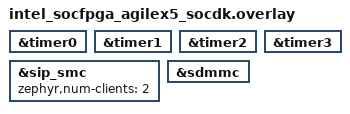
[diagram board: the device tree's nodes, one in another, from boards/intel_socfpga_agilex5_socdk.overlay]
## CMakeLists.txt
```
# SPDX-License-Identifier: Apache-2.0

cmake_minimum_required(VERSION 3.20.0)
find_package(Zephyr REQUIRED HINTS $ENV{ZEPHYR_BASE})
project(shell_module)

target_sources(app PRIVATE src/main.c src/test_module.c)
target_sources_ifdef(CONFIG_SHELL_DYNAMIC_CMDS app PRIVATE src/dynamic_cmd.c)
target_sources_ifdef(CONFIG_SHELL_BACKEND_SERIAL app PRIVATE src/uart_reinit.c)
```

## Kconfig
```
# Config options for logger sample app

# Copyright (c) 2018 Nordic Semiconductor ASA
# SPDX-License-Identifier: Apache-2.0

mainmenu "Shell module sample application"

menu "Application configuration"

config SHELL_FOREGROUND_CMDS
	bool "Shell foreground commands example"
	default y

config SHELL_DYNAMIC_CMDS
	bool "Shell dynamic commands example"
	default y

endmenu

source "Kconfig.zephyr"
```

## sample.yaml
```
sample:
  name: Shell Sample
common:
  filter: not CONFIG_NATIVE_LIBC
  platform_exclude:
    - native_posix
    - native_posix/native/64
tests:
  sample.shell.shell_module:
    filter: CONFIG_SERIAL and dt_chosen_enabled("zephyr,shell-uart")
    tags: shell
    harness: keyboard
    min_ram: 40
    integration_platforms:
      - native_sim
      - intel_socfpga_agilex5_socdk
  sample.shell.shell_module.usb:
    depends_on: usb_device
    tags:
      - shell
      - usb
    harness: keyboard
    min_ram: 40
    extra_args:
      - OVERLAY_CONFIG="overlay-usb.conf"
      - DTC_OVERLAY_FILE="usb.overlay"
    integration_platforms:
      - native_sim
  sample.shell.shell_module.minimal:
    filter: CONFIG_SERIAL and dt_chosen_enabled("zephyr,shell-uart")
    tags: shell
    harness: keyboard
    extra_args: CONF_FILE="prj_minimal.conf"
    integration_platforms:
      - native_sim
  sample.shell.shell_module.getopt:
    integration_platforms:
      - qemu_x86
    arch_exclude: posix
    filter: CONFIG_SERIAL and dt_chosen_enabled("zephyr,shell-uart") and not CONFIG_NEWLIB_LIBC
    tags: shell
    harness: keyboard
    min_ram: 40
    extra_args: CONF_FILE="prj_getopt.conf"
  sample.shell.shell_module.minimal_rtt:
    filter: CONFIG_HAS_SEGGER_RTT
    tags: shell
    harness: keyboard
    extra_args: CONF_FILE="prj_minimal_rtt.conf"
    integration_platforms:
      - nrf52833dk/nrf52833
  sample.shell.shell_module.bt:
    platform_allow:
      - nrf52840dk/nrf52840
    integration_platforms:
      - nrf52840dk/nrf52840
    tags:
      - shell
      - bluetooth
    filter: CONFIG_DT_HAS_ZEPHYR_NUS_UART_ENABLED
    harness: bluetooth_nus
    arch_exclude:
      - posix
    extra_args:
      - OVERLAY_CONFIG="overlay-bt.conf"
      - DTC_OVERLAY_FILE="bt.overlay"
  sample.shell.shell_module.login:
    filter: CONFIG_SERIAL and dt_chosen_enabled("zephyr,shell-uart")
    tags: shell
    harness: keyboard
    min_ram: 40
    extra_args: CONF_FILE="prj_login.conf"
    integration_platforms:
      - native_sim
  sample.shell.shell_module.robot:
    harness: robot
    harness_config:
      robot_testsuite: shell_module.robot
```

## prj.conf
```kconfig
CONFIG_PRINTK=y
CONFIG_SHELL=y
CONFIG_LOG=y
CONFIG_LOG_CMDS=y
CONFIG_INIT_STACKS=y
CONFIG_THREAD_STACK_INFO=y
CONFIG_KERNEL_SHELL=y
CONFIG_THREAD_MONITOR=y
CONFIG_BOOT_BANNER=n
CONFIG_THREAD_NAME=y
CONFIG_DEVICE_SHELL=y
CONFIG_POSIX_API=y
CONFIG_POSIX_TIMERS=y
CONFIG_DATE_SHELL=y
CONFIG_THREAD_RUNTIME_STATS=y
CONFIG_THREAD_RUNTIME_STATS_USE_TIMING_FUNCTIONS=y
CONFIG_STATS=y
CONFIG_STATS_SHELL=y
```

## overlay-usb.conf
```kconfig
CONFIG_USB_DEVICE_STACK=y
CONFIG_USB_DEVICE_PRODUCT="Zephyr USB shell sample"
CONFIG_SHELL_BACKEND_SERIAL_CHECK_DTR=y
CONFIG_UART_LINE_CTRL=y
CONFIG_USB_DEVICE_INITIALIZE_AT_BOOT=n

# POSIX_TIMERS requires an embedded C library while the native USB driver is incompatible with it.
# So let's disable it. Once USB_NATIVE_POSIX supports embedded C libraries this can be removed.
CONFIG_POSIX_API=n
CONFIG_POSIX_TIMERS=n
# DATE_SHELL requires POSIX_TIMERS
CONFIG_DATE_SHELL=n
```

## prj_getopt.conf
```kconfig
CONFIG_PRINTK=y
CONFIG_SHELL=y
CONFIG_SHELL_GETOPT=y
CONFIG_LOG=y
CONFIG_INIT_STACKS=y
CONFIG_THREAD_STACK_INFO=y
CONFIG_KERNEL_SHELL=y
CONFIG_THREAD_MONITOR=y
CONFIG_BOOT_BANNER=n
CONFIG_THREAD_NAME=y
CONFIG_DEVICE_SHELL=y
CONFIG_POSIX_API=y
CONFIG_POSIX_TIMERS=y
CONFIG_DATE_SHELL=y
CONFIG_THREAD_RUNTIME_STATS=y
```

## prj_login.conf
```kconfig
CONFIG_PRINTK=y
CONFIG_SHELL=y
CONFIG_LOG=y
CONFIG_INIT_STACKS=y
CONFIG_THREAD_STACK_INFO=y
CONFIG_KERNEL_SHELL=y
CONFIG_THREAD_MONITOR=y
CONFIG_BOOT_BANNER=n
CONFIG_THREAD_NAME=y
CONFIG_DEVICE_SHELL=y
CONFIG_POSIX_API=y
CONFIG_POSIX_TIMERS=y
CONFIG_DATE_SHELL=y
CONFIG_THREAD_RUNTIME_STATS=y

CONFIG_SHELL_CMDS_SELECT=y
CONFIG_SHELL_START_OBSCURED=y
CONFIG_SHELL_PROMPT_UART="login: "
CONFIG_SHELL_CMD_ROOT="login"
```

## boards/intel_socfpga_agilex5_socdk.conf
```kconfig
# Copyright (c) 2022-2023, Intel Corporation.
# SPDX-License-Identifier: Apache-2.0

# Misc
CONFIG_HEAP_MEM_POOL_SIZE=16384
CONFIG_SHELL_STACK_SIZE=8192

# Setting the max argc
CONFIG_SHELL_ARGC_MAX=12

# Enable the Zephyr boot banner
CONFIG_BOOT_BANNER=y

# Enable timer driver
CONFIG_COUNTER=y

# Enable Timer shell commands
CONFIG_COUNTER_SHELL=y

#SiP SVC Service
CONFIG_ARM_SIP_SVC_DRIVER=y
CONFIG_ARM_SIP_SVC_SUBSYS=y
CONFIG_ARM_SIP_SVC_SUBSYS_SINGLY_OPEN=y

#SiP SVC Service Shell
CONFIG_ARM_SIP_SVC_SUBSYS_SHELL=y

# Enable File System Shell
CONFIG_FILE_SYSTEM_SHELL=y

# Enable Disk access
CONFIG_DISK_ACCESS=y

# File System Setting
CONFIG_FILE_SYSTEM=y
CONFIG_FAT_FILESYSTEM_ELM=y

# Enable SDMMC
CONFIG_DISK_DRIVER_SDMMC=y

# Enable SDHC
CONFIG_SDHC=y
```

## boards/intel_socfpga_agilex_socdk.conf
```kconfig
# Copyright (c) 2023, Intel Corporation.
# SPDX-License-Identifier: Apache-2.0

# Misc
CONFIG_HEAP_MEM_POOL_SIZE=16384
CONFIG_SHELL_STACK_SIZE=8192

# Setting the max argc
CONFIG_SHELL_ARGC_MAX=12

# Enable the Zephyr boot banner
CONFIG_BOOT_BANNER=y

#SiP SVC Service
CONFIG_ARM_SIP_SVC_DRIVER=y
CONFIG_ARM_SIP_SVC_SUBSYS=y
CONFIG_ARM_SIP_SVC_SUBSYS_SINGLY_OPEN=y

#SiP SVC Service Shell
CONFIG_ARM_SIP_SVC_SUBSYS_SHELL=y
```

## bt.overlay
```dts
/*
 * Copyright (c) 2024 Croxel, Inc.
 *
 * SPDX-License-Identifier: Apache-2.0
 */

/ {
	chosen {
		zephyr,console = &bt_nus_console_uart;
		zephyr,shell-uart = &bt_nus_console_uart;
	};

	bt_nus_console_uart: bt_nus_console_uart {
		compatible = "zephyr,nus-uart";
		rx-fifo-size = <1024>;
		tx-fifo-size = <1024>;
	};
};
```

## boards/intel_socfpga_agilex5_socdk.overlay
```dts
/*
 * Copyright (C) 2023 Intel Corporation
 * SPDX-License-Identifier: Apache-2.0
 */

/*
 * The overlay file should be used to enable any
 * dts nodes required by this shell application for this
 * board.
 *
 * Nothing here as of now.
 */

&timer0 {
	status = "okay";
};

&timer1 {
	status = "okay";
};

&timer2 {
	status = "okay";
};

&timer3 {
	status = "okay";
};

&sip_smc {
	status = "okay";
	zephyr,num-clients = <2>;
};

&sdmmc {
	status = "okay";
};
```

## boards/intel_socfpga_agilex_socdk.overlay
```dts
/*
 * Copyright (C) 2023 Intel Corporation
 * SPDX-License-Identifier: Apache-2.0
 */

/*
 * The overlay file should be used to enable any
 * dts nodes required by this shell application for this
 * board.
 */

&sip_smc {
	status = "okay";
	zephyr,num-clients = <2>;
};
```

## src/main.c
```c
/*
 * Copyright (c) 2015 Intel Corporation
 *
 * SPDX-License-Identifier: Apache-2.0
 */

#include <zephyr/kernel.h>
#include <zephyr/shell/shell.h>
#include <zephyr/version.h>
#include <zephyr/logging/log.h>
#include <stdlib.h>
#include <zephyr/drivers/uart.h>
#include <zephyr/usb/usb_device.h>
#include <ctype.h>

#ifdef CONFIG_ARCH_POSIX
#include <unistd.h>
#else
#include <zephyr/posix/unistd.h>
#endif

LOG_MODULE_REGISTER(app);

extern void foo(void);

void timer_expired_handler(struct k_timer *timer)
{
	LOG_INF("Timer expired.");

	/* Call another module to present logging from multiple sources. */
	foo();
}

K_TIMER_DEFINE(log_timer, timer_expired_handler, NULL);

static int cmd_log_test_start(const struct shell *sh, size_t argc,
			      char **argv, uint32_t period)
{
	ARG_UNUSED(argv);

	k_timer_start(&log_timer, K_MSEC(period), K_MSEC(period));
	shell_print(sh, "Log test started\n");

	return 0;
}

static int cmd_log_test_start_demo(const struct shell *sh, size_t argc,
				   char **argv)
{
	return cmd_log_test_start(sh, argc, argv, 200);
}

static int cmd_log_test_start_flood(const struct shell *sh, size_t argc,
				    char **argv)
{
	return cmd_log_test_start(sh, argc, argv, 10);
}

static int cmd_log_test_stop(const struct shell *sh, size_t argc,
			     char **argv)
{
	ARG_UNUSED(argc);
	ARG_UNUSED(argv);

	k_timer_stop(&log_timer);
	shell_print(sh, "Log test stopped");

	return 0;
}

SHELL_STATIC_SUBCMD_SET_CREATE(sub_log_test_start,
	SHELL_CMD_ARG(demo, NULL,
		  "Start log timer which generates log message every 200ms.",
		  cmd_log_test_start_demo, 1, 0),
	SHELL_CMD_ARG(flood, NULL,
		  "Start log timer which generates log message every 10ms.",
		  cmd_log_test_start_flood, 1, 0),
	SHELL_SUBCMD_SET_END /* Array terminated. */
);
SHELL_STATIC_SUBCMD_SET_CREATE(sub_log_test,
	SHELL_CMD_ARG(start, &sub_log_test_start, "Start log test", NULL, 2, 0),
	SHELL_CMD_ARG(stop, NULL, "Stop log test.", cmd_log_test_stop, 1, 0),
	SHELL_SUBCMD_SET_END /* Array terminated. */
);

SHELL_CMD_REGISTER(log_test, &sub_log_test, "Log test", NULL);

static int cmd_demo_ping(const struct shell *sh, size_t argc, char **argv)
{
	ARG_UNUSED(argc);
	ARG_UNUSED(argv);

	shell_print(sh, "pong");

	return 0;
}

static int cmd_demo_board(const struct shell *sh, size_t argc, char **argv)
{
	ARG_UNUSED(argc);
	ARG_UNUSED(argv);

	shell_print(sh, CONFIG_BOARD);

	return 0;
}

#if defined CONFIG_SHELL_GETOPT
/* Thread save usage */
static int cmd_demo_getopt_ts(const struct shell *sh, size_t argc,
			      char **argv)
{
	struct getopt_state *state;
	char *cvalue = NULL;
	int aflag = 0;
	int bflag = 0;
	int c;

	while ((c = getopt(argc, argv, "abhc:")) != -1) {
		state = getopt_state_get();
		switch (c) {
		case 'a':
			aflag = 1;
			break;
		case 'b':
			bflag = 1;
			break;
		case 'c':
			cvalue = state->optarg;
			break;
		case 'h':
			/* When getopt is active shell is not parsing
			 * command handler to print help message. It must
			 * be done explicitly.
			 */
			shell_help(sh);
			return SHELL_CMD_HELP_PRINTED;
		case '?':
			if (state->optopt == 'c') {
				shell_print(sh,
					"Option -%c requires an argument.",
					state->optopt);
			} else if (isprint(state->optopt) != 0) {
				shell_print(sh,
					"Unknown option `-%c'.",
					state->optopt);
			} else {
				shell_print(sh,
					"Unknown option character `\\x%x'.",
					state->optopt);
			}
			return 1;
		default:
			break;
		}
	}

	shell_print(sh, "aflag = %d, bflag = %d", aflag, bflag);
	return 0;
}

static int cmd_demo_getopt(const struct shell *sh, size_t argc,
			      char **argv)
{
	char *cvalue = NULL;
	int aflag = 0;
	int bflag = 0;
	int c;

	while ((c = getopt(argc, argv, "abhc:")) != -1) {
		switch (c) {
		case 'a':
			aflag = 1;
			break;
		case 'b':
			bflag = 1;
			break;
		case 'c':
			cvalue = optarg;
			break;
		case 'h':
			/* When getopt is active shell is not parsing
			 * command handler to print help message. It must
			 * be done explicitly.
			 */
			shell_help(sh);
			return SHELL_CMD_HELP_PRINTED;
		case '?':
			if (optopt == 'c') {
				shell_print(sh,
					"Option -%c requires an argument.",
					optopt);
			} else if (isprint(optopt) != 0) {
				shell_print(sh, "Unknown option `-%c'.",
					optopt);
			} else {
				shell_print(sh,
					"Unknown option character `\\x%x'.",
					optopt);
			}
			return 1;
		default:
			break;
		}
	}

	shell_print(sh, "aflag = %d, bflag = %d", aflag, bflag);
	return 0;
}
#endif

static int cmd_demo_params(const struct shell *sh, size_t argc, char **argv)
{
	shell_print(sh, "argc = %zd", argc);
	for (size_t cnt = 0; cnt < argc; cnt++) {
		shell_print(sh, "  argv[%zd] = %s", cnt, argv[cnt]);
	}

	return 0;
}

static int cmd_demo_hexdump(const struct shell *sh, size_t argc, char **argv)
{
	shell_print(sh, "argc = %zd", argc);
	for (size_t cnt = 0; cnt < argc; cnt++) {
		shell_print(sh, "argv[%zd]", cnt);
		shell_hexdump(sh, argv[cnt], strlen(argv[cnt]));
	}

	return 0;
}

static int cmd_version(const struct shell *sh, size_t argc, char **argv)
{
	ARG_UNUSED(argc);
	ARG_UNUSED(argv);

	shell_print(sh, "Zephyr version %s", KERNEL_VERSION_STRING);

	return 0;
}

#define DEFAULT_PASSWORD "zephyr"

static void login_init(void)
{
	printk("Shell Login Demo\nHint: password = %s\n", DEFAULT_PASSWORD);
	if (!CONFIG_SHELL_CMD_ROOT[0]) {
		shell_set_root_cmd("login");
	}
}

static int check_passwd(char *passwd)
{
	/* example only -- not recommended for production use */
	return strcmp(passwd, DEFAULT_PASSWORD);
}

static int cmd_login(const struct shell *sh, size_t argc, char **argv)
{
	static uint32_t attempts;

	if (check_passwd(argv[1]) != 0) {
		shell_error(sh, "Incorrect password!");
		attempts++;
		if (attempts > 3) {
			k_sleep(K_SECONDS(attempts));
		}
		return -EINVAL;
	}

	/* clear history so password not visible there */
	z_shell_history_purge(sh->history);
	shell_obscure_set(sh, false);
	shell_set_root_cmd(NULL);
	shell_prompt_change(sh, "uart:~$ ");
	shell_print(sh, "Shell Login Demo\n");
	shell_print(sh, "Hit tab for help.\n");
	attempts = 0;
	return 0;
}

static int cmd_logout(const struct shell *sh, size_t argc, char **argv)
{
	shell_set_root_cmd("login");
	shell_obscure_set(sh, true);
	shell_prompt_change(sh, "login: ");
	shell_print(sh, "\n");
	return 0;
}

static int set_bypass(const struct shell *sh, shell_bypass_cb_t bypass)
{
	static bool in_use;

	if (bypass && in_use) {
		shell_error(sh, "Sample supports setting bypass on single instance.");

		return -EBUSY;
	}

	in_use = !in_use;
	if (in_use) {
		shell_print(sh, "Bypass started, press ctrl-x ctrl-q to escape");
		in_use = true;
	}

	shell_set_bypass(sh, bypass);

	return 0;
}

#define CHAR_1 0x18
#define CHAR_2 0x11

static void bypass_cb(const struct shell *sh, uint8_t *data, size_t len)
{
	static uint8_t tail;
	bool escape = false;

	/* Check if escape criteria is met. */
	if (tail == CHAR_1 && data[0] == CHAR_2) {
		escape = true;
	} else {
		for (int i = 0; i < (len - 1); i++) {
			if (data[i] == CHAR_1 && data[i + 1] == CHAR_2) {
				escape = true;
				break;
			}
		}
	}

	if (escape) {
		shell_print(sh, "Exit bypass");
		set_bypass(sh, NULL);
		tail = 0;
		return;
	}

	/* Store last byte for escape sequence detection */
	tail = data[len - 1];

	/* Do the data processing. */
	for (int i = 0; i < len; i++) {
		shell_fprintf(sh, SHELL_INFO, "%02x ", data[i]);
	}
	shell_fprintf(sh, SHELL_INFO, "| ");

	for (int i = 0; i < len; i++) {
		shell_fprintf(sh, SHELL_INFO, "%c", data[i]);
	}
	shell_fprintf(sh, SHELL_INFO, "\n");

}

static int cmd_bypass(const struct shell *sh, size_t argc, char **argv)
{
	return set_bypass(sh, bypass_cb);
}

static int cmd_dict(const struct shell *sh, size_t argc, char **argv,
		    void *data)
{
	int val = (intptr_t)data;

	shell_print(sh, "(syntax, value) : (%s, %d)", argv[0], val);

	return 0;
}

SHELL_SUBCMD_DICT_SET_CREATE(sub_dict_cmds, cmd_dict,
	(value_0, 0, "value 0"), (value_1, 1, "value 1"),
	(value_2, 2, "value 2"), (value_3, 3, "value 3")
);

SHELL_STATIC_SUBCMD_SET_CREATE(sub_demo,
	SHELL_CMD(dictionary, &sub_dict_cmds, "Dictionary commands", NULL),
	SHELL_CMD(hexdump, NULL, "Hexdump params command.", cmd_demo_hexdump),
	SHELL_CMD(params, NULL, "Print params command.", cmd_demo_params),
	SHELL_CMD(ping, NULL, "Ping command.", cmd_demo_ping),
	SHELL_CMD(board, NULL, "Show board name command.", cmd_demo_board),
#if defined CONFIG_SHELL_GETOPT
	SHELL_CMD(getopt_thread_safe, NULL,
		  "Cammand using getopt in thread safe way"
		  " looking for: \"abhc:\".",
		  cmd_demo_getopt_ts),
	SHELL_CMD(getopt, NULL, "Cammand using getopt in non thread safe way"
		  " looking for: \"abhc:\".\n", cmd_demo_getopt),
#endif
	SHELL_SUBCMD_SET_END /* Array terminated. */
);
SHELL_CMD_REGISTER(demo, &sub_demo, "Demo commands", NULL);

SHELL_CMD_ARG_REGISTER(version, NULL, "Show kernel version", cmd_version, 1, 0);

SHELL_CMD_ARG_REGISTER(bypass, NULL, "Bypass shell", cmd_bypass, 1, 0);

SHELL_COND_CMD_ARG_REGISTER(CONFIG_SHELL_START_OBSCURED, login, NULL,
			    "<password>", cmd_login, 2, 0);

SHELL_COND_CMD_REGISTER(CONFIG_SHELL_START_OBSCURED, logout, NULL,
			"Log out.", cmd_logout);


/* Create a set of commands. Commands to this set are added using @ref SHELL_SUBCMD_ADD
 * and @ref SHELL_SUBCMD_COND_ADD.
 */
SHELL_SUBCMD_SET_CREATE(sub_section_cmd, (section_cmd));

static int cmd1_handler(const struct shell *sh, size_t argc, char **argv)
{
	ARG_UNUSED(sh);
	ARG_UNUSED(argc);
	ARG_UNUSED(argv);

	shell_print(sh, "cmd1 executed");

	return 0;
}

/* Create a set of subcommands for "section_cmd cm1". */
SHELL_SUBCMD_SET_CREATE(sub_section_cmd1, (section_cmd, cmd1));

/* Add command to the set. Subcommand set is identify by parent shell command. */
SHELL_SUBCMD_ADD((section_cmd), cmd1, &sub_section_cmd1, "help for cmd1", cmd1_handler, 1, 0);

SHELL_CMD_REGISTER(section_cmd, &sub_section_cmd,
		   "Demo command using section for subcommand registration", NULL);

int main(void)
{
	if (IS_ENABLED(CONFIG_SHELL_START_OBSCURED)) {
		login_init();
	}

#if DT_NODE_HAS_COMPAT(DT_CHOSEN(zephyr_shell_uart), zephyr_cdc_acm_uart)
	const struct device *dev;
	uint32_t dtr = 0;

	dev = DEVICE_DT_GET(DT_CHOSEN(zephyr_shell_uart));
	if (!device_is_ready(dev) || usb_enable(NULL)) {
		return 0;
	}

	while (!dtr) {
		uart_line_ctrl_get(dev, UART_LINE_CTRL_DTR, &dtr);
		k_sleep(K_MSEC(100));
	}
#endif
	return 0;
}
```

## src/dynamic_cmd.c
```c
/*
 * Copyright (c) 2018 Nordic Semiconductor ASA
 *
 * SPDX-License-Identifier: Apache-2.0
 */

#include <zephyr/shell/shell.h>
#include <ctype.h>
#include <stdio.h>
#include <stdlib.h>

#define MAX_CMD_CNT (20u)
#define MAX_CMD_LEN (33u)

/* buffer holding dynamically created user commands */
static char dynamic_cmd_buffer[MAX_CMD_CNT][MAX_CMD_LEN];
/* commands counter */
static uint8_t dynamic_cmd_cnt;

typedef int cmp_t(const void *, const void *);
extern void qsort(void *a, size_t n, size_t es, cmp_t *cmp);

/* function required by qsort */
static int string_cmp(const void *p_a, const void *p_b)
{
	return strcmp((const char *)p_a, (const char *)p_b);
}

static int cmd_dynamic_add(const struct shell *sh,
			   size_t argc, char **argv)
{
	uint16_t cmd_len;
	uint8_t idx;

	ARG_UNUSED(argc);

	if (dynamic_cmd_cnt >= MAX_CMD_CNT) {
		shell_error(sh, "command limit reached");
		return -ENOEXEC;
	}

	cmd_len = strlen(argv[1]);

	if (cmd_len >= MAX_CMD_LEN) {
		shell_error(sh, "too long command");
		return -ENOEXEC;
	}

	for (idx = 0U; idx < cmd_len; idx++) {
		if (isalnum((int)(argv[1][idx])) == 0) {
			shell_error(sh,
				    "bad command name - please use only"
				    " alphanumerical characters");
			return -ENOEXEC;
		}
	}

	for (idx = 0U; idx < MAX_CMD_CNT; idx++) {
		if (!strcmp(dynamic_cmd_buffer[idx], argv[1])) {
			shell_error(sh, "duplicated command");
			return -ENOEXEC;
		}
	}

	sprintf(dynamic_cmd_buffer[dynamic_cmd_cnt++], "%s", argv[1]);

	qsort(dynamic_cmd_buffer, dynamic_cmd_cnt,
	      sizeof(dynamic_cmd_buffer[0]), string_cmp);

	shell_print(sh, "command added successfully");

	return 0;
}

static int cmd_dynamic_execute(const struct shell *sh,
			       size_t argc, char **argv)
{
	ARG_UNUSED(argc);
	ARG_UNUSED(argv);

	for (uint8_t idx = 0; idx <  dynamic_cmd_cnt; idx++) {
		if (!strcmp(dynamic_cmd_buffer[idx], argv[1])) {
			shell_print(sh, "dynamic command: %s", argv[1]);
			return 0;
		}
	}

	shell_error(sh, "%s: unknown parameter: %s", argv[0], argv[1]);

	return -ENOEXEC;
}

static int cmd_dynamic_remove(const struct shell *sh, size_t argc,
			      char **argv)
{
	ARG_UNUSED(argc);
	ARG_UNUSED(argv);

	for (uint8_t idx = 0; idx <  dynamic_cmd_cnt; idx++) {
		if (!strcmp(dynamic_cmd_buffer[idx], argv[1])) {
			if (idx == MAX_CMD_CNT - 1) {
				dynamic_cmd_buffer[idx][0] = '\0';
			} else {
				memmove(dynamic_cmd_buffer[idx],
					dynamic_cmd_buffer[idx + 1],
					sizeof(dynamic_cmd_buffer[idx]) *
					(dynamic_cmd_cnt - idx));
			}

			--dynamic_cmd_cnt;
			shell_print(sh, "command removed successfully");
			return 0;
		}
	}
	shell_error(sh, "did not find command: %s", argv[1]);

	return -ENOEXEC;
}

static int cmd_dynamic_show(const struct shell *sh,
			    size_t argc, char **argv)
{
	ARG_UNUSED(argc);
	ARG_UNUSED(argv);

	if (dynamic_cmd_cnt == 0U) {
		shell_warn(sh, "Please add some commands first.");
		return -ENOEXEC;
	}

	shell_print(sh, "Dynamic command list:");

	for (uint8_t i = 0; i < dynamic_cmd_cnt; i++) {
		shell_print(sh, "[%3d] %s", i, dynamic_cmd_buffer[i]);
	}

	return 0;
}

/* dynamic command creation */
static void dynamic_cmd_get(size_t idx, struct shell_static_entry *entry)
{
	if (idx < dynamic_cmd_cnt) {
		/* m_dynamic_cmd_buffer must be sorted alphabetically to ensure
		 * correct CLI completion
		 */
		entry->syntax = dynamic_cmd_buffer[idx];
		entry->handler  = NULL;
		entry->subcmd = NULL;
		entry->help = "Show dynamic command name.";
	} else {
		/* if there are no more dynamic commands available syntax
		 * must be set to NULL.
		 */
		entry->syntax = NULL;
	}
}

SHELL_DYNAMIC_CMD_CREATE(m_sub_dynamic_set, dynamic_cmd_get);
SHELL_STATIC_SUBCMD_SET_CREATE(m_sub_dynamic,
	SHELL_CMD_ARG(add, NULL,
		"Add a new dynamic command.\nExample usage: [ dynamic add test "
		"] will add a dynamic command 'test'.\nIn this example, command"
		" name length is limited to 32 chars. You can add up to 20"
		" commands. Commands are automatically sorted to ensure correct"
		" shell completion.",
		cmd_dynamic_add, 2, 0),
	SHELL_CMD_ARG(execute, &m_sub_dynamic_set,
		"Execute a command.", cmd_dynamic_execute, 2, 0),
	SHELL_CMD_ARG(remove, &m_sub_dynamic_set,
		"Remove a command.", cmd_dynamic_remove, 2, 0),
	SHELL_CMD_ARG(show, NULL,
		"Show all added dynamic commands.", cmd_dynamic_show, 1, 0),
	SHELL_SUBCMD_SET_END
);

SHELL_CMD_REGISTER(dynamic, &m_sub_dynamic,
		   "Demonstrate dynamic command usage.", NULL);
```

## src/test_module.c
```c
/*
 * Copyright (c) 2018 Nordic Semiconductor ASA
 *
 * SPDX-License-Identifier: Apache-2.0
 */

#include <zephyr/logging/log.h>
#include <zephyr/shell/shell.h>
LOG_MODULE_REGISTER(app_test);

void foo(void)
{
	LOG_INF("info message");
	LOG_WRN("warning message");
	LOG_ERR("err message");
}

/* Commands below are added using memory section approach which allows to build
 * a set of subcommands from multiple files.
 */
static int cmd2_handler(const struct shell *sh, size_t argc, char **argv)
{
	ARG_UNUSED(sh);
	ARG_UNUSED(argc);
	ARG_UNUSED(argv);

	shell_print(sh, "cmd2 executed");

	return 0;
}

SHELL_SUBCMD_ADD((section_cmd), cmd2, NULL, "help for cmd2", cmd2_handler, 1, 0);

static int sub_cmd1_handler(const struct shell *sh, size_t argc, char **argv)
{
	ARG_UNUSED(sh);
	ARG_UNUSED(argc);
	ARG_UNUSED(argv);

	shell_print(sh, "sub cmd1 executed");

	return 0;
}

SHELL_SUBCMD_COND_ADD(1, (section_cmd, cmd1), sub_cmd1, NULL, "help for cmd2",
			sub_cmd1_handler, 1, 0);
```

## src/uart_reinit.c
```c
/*
 * Copyright (c) 2021 Nordic Semiconductor ASA
 *
 * SPDX-License-Identifier: Apache-2.0
 */
#include <zephyr/shell/shell.h>
#include <zephyr/shell/shell_uart.h>
#include <zephyr/drivers/uart.h>
#include <zephyr/device.h>

void shell_init_from_work(struct k_work *work)
{
	const struct device *const dev = DEVICE_DT_GET(DT_CHOSEN(zephyr_shell_uart));
	bool log_backend = CONFIG_SHELL_BACKEND_SERIAL_LOG_LEVEL > 0;
	uint32_t level =
		(CONFIG_SHELL_BACKEND_SERIAL_LOG_LEVEL > LOG_LEVEL_DBG) ?
		CONFIG_LOG_MAX_LEVEL : CONFIG_SHELL_BACKEND_SERIAL_LOG_LEVEL;

	shell_init(shell_backend_uart_get_ptr(), dev,
		   shell_backend_uart_get_ptr()->ctx->cfg.flags,
		   log_backend, level);
}

static void shell_reinit_trigger(void)
{
	static struct k_work shell_init_work;

	k_work_init(&shell_init_work, shell_init_from_work);
	int err = k_work_submit(&shell_init_work);

	(void)err;
	__ASSERT_NO_MSG(err >= 0);
}

static void direct_uart_callback(const struct device *dev, void *user_data)
{
	static uint8_t buf[1];
	static bool tx_busy;

	uart_irq_update(dev);


	if (uart_irq_rx_ready(dev)) {
		while (uart_fifo_read(dev, buf, sizeof(buf))) {
			if (!tx_busy) {
				uart_irq_tx_enable(dev);
			}
		}
	}

	if (uart_irq_tx_ready(dev)) {
		if (!tx_busy) {
			(void)uart_fifo_fill(dev, buf, sizeof(buf));
			tx_busy = true;
		} else {
			tx_busy = false;
			uart_irq_tx_disable(dev);
			if (buf[0] == 'x') {
				uart_irq_rx_disable(dev);
				shell_reinit_trigger();
			}
		}
	}
}

static void uart_poll_timer_stopped(struct k_timer *timer)
{
	shell_reinit_trigger();
}

static void uart_poll_timeout(struct k_timer *timer)
{
	char c;
	const struct device *dev = k_timer_user_data_get(timer);

	while (uart_poll_in(dev, &c) == 0) {
		if (c != 'x') {
			uart_poll_out(dev, c);
		} else {
			k_timer_stop(timer);
		}
	}
}

K_TIMER_DEFINE(uart_poll_timer, uart_poll_timeout, uart_poll_timer_stopped);

static void shell_uninit_cb(const struct shell *sh, int res)
{
	__ASSERT_NO_MSG(res >= 0);
	const struct device *const dev = DEVICE_DT_GET(DT_CHOSEN(zephyr_shell_uart));

	if (IS_ENABLED(CONFIG_SHELL_BACKEND_SERIAL_INTERRUPT_DRIVEN)) {
		/* connect uart to my handler */
		uart_irq_callback_user_data_set(dev, direct_uart_callback, NULL);
		uart_irq_rx_enable(dev);
	} else {
		k_timer_user_data_set(&uart_poll_timer, (void *)dev);
		k_timer_start(&uart_poll_timer, K_MSEC(10), K_MSEC(10));
	}
}

static int cmd_uart_release(const struct shell *sh, size_t argc, char **argv)
{
	ARG_UNUSED(argc);
	ARG_UNUSED(argv);

	if (sh != shell_backend_uart_get_ptr()) {
		shell_error(sh, "Command dedicated for shell over uart");
		return -EINVAL;
	}

	shell_print(sh, "Uninitializing shell, use 'x' to reinitialize");
	shell_uninit(sh, shell_uninit_cb);

	return 0;
}

SHELL_CMD_REGISTER(shell_uart_release, NULL,
		"Uninitialize shell instance and release uart, start loopback "
		"on uart. Shell instance is reinitialized when 'x' is pressed",
		cmd_uart_release);
```
